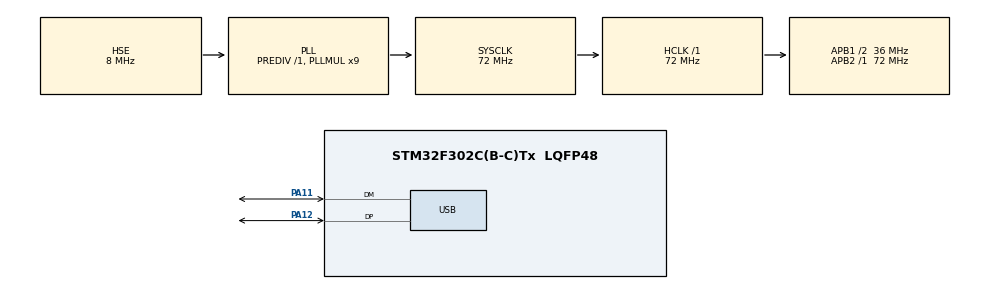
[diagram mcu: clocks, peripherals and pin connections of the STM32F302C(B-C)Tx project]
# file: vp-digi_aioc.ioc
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Mcu.Family=STM32F3
Mcu.Name=STM32F302C(B-C)Tx
Mcu.Package=LQFP48
NVIC.PriorityGroup=NVIC_PRIORITYGROUP_4
NVIC.USB_HP_CAN_TX_IRQn=true\:0\:0\:false\:false\:true\:true\:true\:true
NVIC.USB_LP_CAN_RX0_IRQn=true\:0\:0\:false\:false\:true\:true\:true\:true
PA11.Mode=Device
PA11.Signal=USB_DM
PA12.Mode=Device
PA12.Signal=USB_DP
PA13.Mode=Serial_Wire
PA13.Signal=SYS_JTMS-SWDIO
PA14.Mode=Serial_Wire
PA14.Signal=SYS_JTCK-SWCLK
PF0-OSC_IN.Mode=HSE-External-Oscillator
PF0-OSC_IN.Signal=RCC_OSC_IN
PF1-OSC_OUT.Mode=HSE-External-Oscillator
PF1-OSC_OUT.Signal=RCC_OSC_OUT
ProjectManager.HeapSize=0x200
ProjectManager.StackSize=0x400
ProjectManager.TargetToolchain=STM32CubeIDE
RCC.AHBFreq_Value=72000000
RCC.APB1CLKDivider=RCC_HCLK_DIV2
RCC.APB1Freq_Value=36000000
RCC.APB1TimFreq_Value=72000000
RCC.APB2Freq_Value=72000000
RCC.APB2TimFreq_Value=72000000
RCC.CortexFreq_Value=72000000
RCC.HCLKFreq_Value=72000000
RCC.HSE_VALUE=8000000
RCC.HSI_VALUE=8000000
RCC.LSE_VALUE=32768
RCC.PLLMUL=RCC_PLL_MUL9
RCC.PRESCALERUSB=RCC_USBCLKSOURCE_PLL_DIV1_5
RCC.SYSCLKFreq_VALUE=72000000
RCC.SYSCLKSourceVirtual=RCC_SYSCLKSOURCE_PLLCLK
RCC.USBFreq_Value=48000000
USB_DEVICE.APP_RX_DATA_SIZE=512
USB_DEVICE.APP_TX_DATA_SIZE=256
USB_DEVICE.CLASS_NAME_FS=CDC
USB_DEVICE.CONFIGURATION_STRING_CDC_FS=VP-Digi
USB_DEVICE.INTERFACE_STRING_CDC_FS=VP-Digi
USB_DEVICE.MANUFACTURER_STRING=SQ8L
USB_DEVICE.PRODUCT_STRING_CDC_FS=VP-Digi AIOC
USB_DEVICE.USBD_MAX_STR_DESC_SIZ=32
USB_DEVICE.USBD_SELF_POWERED=0
USB_DEVICE.VirtualMode=Cdc
USB_DEVICE.VirtualModeFS=Cdc_FS
VP_USB_DEVICE_VS_USB_DEVICE_CDC_FS.Mode=CDC_FS
board=custom

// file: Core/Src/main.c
/* USER CODE BEGIN Header */
/*
Copyright 2020-2026 Piotr Wilkon

This file is part of VP-Digi.

VP-Digi is free software: you can redistribute it and/or modify
it under the terms of the GNU General Public License as published by
the Free Software Foundation; either version 3 of the License, or
(at your option) any later version.

VP-Digi is distributed in the hope that it will be useful,
but WITHOUT ANY WARRANTY; without even the implied warranty of
MERCHANTABILITY or FITNESS FOR A PARTICULAR PURPOSE.  See the
GNU General Public License for more details.

You should have received a copy of the GNU General Public License
along with VP-Digi.  If not, see <http://www.gnu.org/licenses/>.
*/

/**
 ******************************************************************************
 * @file           : main.c
 * @brief          : Main program body
 ******************************************************************************
 * @attention
 *
 * Copyright (c) 2025 STMicroelectronics.
 * All rights reserved.
 *
 * This software is licensed under terms that can be found in the LICENSE file
 * in the root directory of this software component.
 * If no LICENSE file comes with this software, it is provided AS-IS.
 *
 ******************************************************************************
 */
/* USER CODE END Header */
#include "main.h"
#include "usb_device.h"
#include "gpio.h"

/* USER CODE BEGIN Includes */
#include <stdint.h>
#include "modem.h"
#include "ax25.h"
#include "digipeater.h"
#include "common.h"
#include "drivers/watchdog.h"
#include "beacon.h"
#include "terminal.h"
#include "config.h"
#include "uart.h"
#include "drivers/usb.h"
#include "kiss.h"
#ifdef ENABLE_FX25
#include "fx25.h"
#endif
/* USER CODE END Includes */

void SystemClock_Config(void);

/* USER CODE BEGIN 0 */
/**
 * @brief Handle received frame
 */
static void handleFrame(void)
{
	uint8_t modemBitmap = Ax25GetReceivedFrameBitmap(); // store states
	Ax25ClearReceivedFrameBitmap();

	uint8_t *buf;
	uint16_t size = 0;
	int8_t peak = 0;
	int8_t valley = 0;
	uint8_t signalLevel = 0;
	uint8_t fixed = 0;

	while (Ax25ReadNextRxFrame(&buf, &size, &peak, &valley, &signalLevel, &fixed))
	{
		if(DigiCheckFilter(&buf[7]) || !GeneralConfig.kissFilter)
			TermSendToAllN(MODE_KISS, buf, size);

		if ((UartUsb.mode == MODE_MONITOR)
#ifdef BLUE_PILL
		|| (Uart1.mode == MODE_MONITOR)
		|| (Uart2.mode == MODE_MONITOR)
#endif
		)
		{
			char str[20];
			char *pstr = str;

			if(signalLevel > 70)
			{
				TermSendToAll(MODE_MONITOR, "\r\nInput level too high! Please reduce so most stations are around 30-50%.\r\n");
			}
			else if (signalLevel < 5)
			{
				TermSendToAll(MODE_MONITOR, "\r\nInput level too low! Please increase so most stations are around 30-50%.\r\n");
			}
#ifdef ENABLE_FX25
			if(fixed != AX25_NOT_FX25)
				TermSendToAll(MODE_MONITOR, "(FX.25)");
			else
#endif
				TermSendToAll(MODE_MONITOR, "(AX.25)");
			TermSendToAll(MODE_MONITOR, " Frame received [");
			for(uint8_t i = 0; i < ModemGetDemodulatorCount(); i++)
			{
				if (modemBitmap & (1 << i))
				{
					enum ModemPrefilter m = ModemGetFilterType(i);
					switch (m)
					{
						case PREFILTER_PREEMPHASIS:
							*pstr++ = 'P';
							break;
						case PREFILTER_DEEMPHASIS:
							*pstr++ = 'D';
							break;
						case PREFILTER_FLAT:
							*pstr++ = 'F';
							break;
						case PREFILTER_NONE:
							*pstr++ = 'N';
							break;
					}
				}
				else
					*pstr++ = '_';
			}
			*pstr++ = '\0';
			TermSendToAll(MODE_MONITOR, str);
			TermSendToAll(MODE_MONITOR, "], ");
#ifdef ENABLE_FX25
			if(fixed != AX25_NOT_FX25)
			{
				IntToStr(fixed, str);
				TermSendToAll(MODE_MONITOR, str);
				TermSendToAll(MODE_MONITOR, " bytes fixed, ");
			}
#endif
			TermSendToAll(MODE_MONITOR, "signal level ");
			IntToStr(signalLevel, str);
			TermSendToAll(MODE_MONITOR, str);
			TermSendToAll(MODE_MONITOR, "% (");
			IntToStr(peak, str);
			TermSendToAll(MODE_MONITOR, str);
			TermSendToAll(MODE_MONITOR, "%/");
			IntToStr(valley, str);
			TermSendToAll(MODE_MONITOR, str);
			TermSendToAll(MODE_MONITOR, "%): ");

			SendTNC2(buf, size);
			TermSendToAll(MODE_MONITOR, "\r\n");
		}

		DigiDigipeat(buf, size);
	}
}
/* USER CODE END 0 */

int main(void)
{

  /* MCU Configuration--------------------------------------------------------*/

  /* Reset of all peripherals, Initializes the Flash interface and the Systick. */
  HAL_Init();

  /* Configure the system clock */
  SystemClock_Config();

  /* USER CODE BEGIN SysInit */
	HAL_SetTickFreq(VPDIGI_HAL_TICK_FREQUENCY);

	USB_FORCE_REENUMERATION();
  /* USER CODE END SysInit */

  /* Initialize all configured peripherals */
  MX_GPIO_Init();
  MX_USB_DEVICE_Init();
  /* USER CODE BEGIN 2 */
	WdogInit(); // initialize watchdog

	memset(BeaconConfig, 0, sizeof(BeaconConfig));
	memset(&Ax25Config, 0, sizeof(Ax25Config));
	memset(&ModemConfig, 0, sizeof(ModemConfig));
	memset(&DigiConfig, 0, sizeof(DigiConfig));

	// set some initial values in case there is no configuration saved in memory
#ifdef BLUE_PILL
	Uart1.config.baudrate = 9600;
	Uart1.config.defaultMode = MODE_KISS;
	Uart2.config.baudrate = 9600;
	Uart2.config.defaultMode = MODE_KISS;
#endif
	UartUsb.config.defaultMode = MODE_KISS;
	ModemConfig.usePWM = 1; //use PWM in non-AIOC versions
	ModemConfig.flatAudioIn = 0; //no flat audio
	ModemConfig.pttOutput = 0; //primary PTT in AIOC versions
	ModemConfig.txLevel = 100; //100% - only in AIOC versions
	Ax25Config.quietTime = 300;
	Ax25Config.txDelayLength = 300;
	Ax25Config.txTailLength = 30;
	Ax25Config.fx25 = 0;
	DigiConfig.dupeTime = 30;

	ConfigRead();

	ModemInit();
	Ax25Init();
#ifdef ENABLE_FX25
	Fx25Init();
#endif

	DigiInitialize();

#ifdef BLUE_PILL
	UartInit(&Uart1, UART_LL_UART1_STRUCTURE, Uart1.config.baudrate);
	UartConfig(&Uart1, 1);
	UartInit(&Uart2, UART_LL_UART2_STRUCTURE, Uart2.config.baudrate);
	UartConfig(&Uart2, 1);
#endif

	UartInit(&UartUsb, NULL, 1);
	UartConfig(&UartUsb, 1);

	BeaconInit();
  /* USER CODE END 2 */

  /* Infinite loop */
	while (1)
	{

    /* USER CODE BEGIN 3 */
		WdogReset();

		if (Ax25GetReceivedFrameBitmap())
			handleFrame();

		DigiUpdateState(); // update digipeater state

		Ax25TransmitBuffer(); // transmit buffer (will return if nothing to be transmitted)

		Ax25TransmitCheck(); // check for pending transmission request

		if (UartUsb.rxType != DATA_NOTHING)
		{
			TermHandleSpecial(&UartUsb);
			if (UartUsb.rxType == DATA_KISS)
			{
				KissProcess(&UartUsb);
			}
			else if (UartUsb.rxType != DATA_USB)
			{

				TermParse(&UartUsb);
				UartClearRx(&UartUsb);
			}
			// previously there was just UartUsb.rxType = DATA_NOTHING, which could introduce deadlocks
			// assume that we were here, because rxType was DATA_USB, but in the meantime a new USB interrupt fired and rxType changed to DATA_KISS,
			// and the KISS parsing handler would set kissProcessingOngoing to 1. Then, we change rxType to DATA_NOTHING and are left in an incorrect scenario, when
			// rxType is DATA_NOTHING, and kissProcessingOngoing is 1, which is a clear deadlock, because then DATA_KISS can never be reached again.
			// That's why it is necessary to disable interrupts and check one more time for rxType before clearing it
			else
			{
				__disable_irq();
				if (UartUsb.rxType == DATA_USB)
					UartUsb.rxType = DATA_NOTHING;
				__enable_irq();
			}
		}
#ifdef BLUE_PILL
		if (Uart1.rxType != DATA_NOTHING)
		{
			if (Uart1.rxType == DATA_KISS)
			{
				KissProcess(&Uart1);
			}
			else
			{
				TermParse(&Uart1);
				UartClearRx(&Uart1);
			}
		}
		if (Uart2.rxType != DATA_NOTHING)
		{
			if (Uart2.rxType == DATA_KISS)
			{
				KissProcess(&Uart2);
			}
			else
			{
				TermParse(&Uart2);
				UartClearRx(&Uart2);
			}
		}
#endif

		BeaconCheck(); // check beacons

		if (HAL_GetTick() > 0xFFFFF000) // going to wrap around soon - hard reset the device
			NVIC_SystemReset();
	}
  /* USER CODE END 3 */
}

void SystemClock_Config(void)
{
  RCC_OscInitTypeDef RCC_OscInitStruct = {0};
  RCC_ClkInitTypeDef RCC_ClkInitStruct = {0};
  RCC_PeriphCLKInitTypeDef PeriphClkInit = {0};

  /** Initializes the RCC Oscillators according to the specified parameters
  * in the RCC_OscInitTypeDef structure.
  */
  RCC_OscInitStruct.OscillatorType = RCC_OSCILLATORTYPE_HSE;
  RCC_OscInitStruct.HSEState = RCC_HSE_ON;
  RCC_OscInitStruct.HSEPredivValue = RCC_HSE_PREDIV_DIV1;
  RCC_OscInitStruct.HSIState = RCC_HSI_ON;
  RCC_OscInitStruct.PLL.PLLState = RCC_PLL_ON;
  RCC_OscInitStruct.PLL.PLLSource = RCC_PLLSOURCE_HSE;
  RCC_OscInitStruct.PLL.PLLMUL = RCC_PLL_MUL9;
  if (HAL_RCC_OscConfig(&RCC_OscInitStruct) != HAL_OK)
  {
    Error_Handler();
  }

  /** Initializes the CPU, AHB and APB buses clocks
  */
  RCC_ClkInitStruct.ClockType = RCC_CLOCKTYPE_HCLK|RCC_CLOCKTYPE_SYSCLK
                              |RCC_CLOCKTYPE_PCLK1|RCC_CLOCKTYPE_PCLK2;
  RCC_ClkInitStruct.SYSCLKSource = RCC_SYSCLKSOURCE_PLLCLK;
  RCC_ClkInitStruct.AHBCLKDivider = RCC_SYSCLK_DIV1;
  RCC_ClkInitStruct.APB1CLKDivider = RCC_HCLK_DIV2;
  RCC_ClkInitStruct.APB2CLKDivider = RCC_HCLK_DIV1;

  if (HAL_RCC_ClockConfig(&RCC_ClkInitStruct, FLASH_LATENCY_2) != HAL_OK)
  {
    Error_Handler();
  }
  PeriphClkInit.PeriphClockSelection = RCC_PERIPHCLK_USB;
  PeriphClkInit.UsbClockSelection = RCC_USBCLKSOURCE_PLL_DIV1_5;
  if (HAL_RCCEx_PeriphCLKConfig(&PeriphClkInit) != HAL_OK)
  {
    Error_Handler();
  }
}

void Error_Handler(void)
{
	__disable_irq();
	while (1)
	{
	}
}
